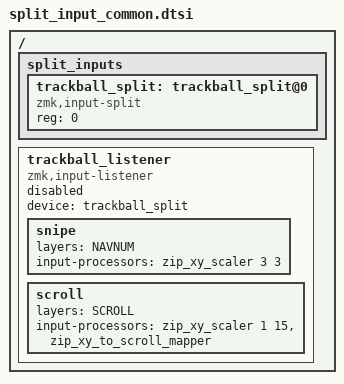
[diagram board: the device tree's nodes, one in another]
#include <dt-bindings/zmk/input_transform.h>
#include <input/processors.dtsi>

#define BASE 0
#define NAVNUM 1
#define SYMBOL 2
#define MEDIA 3
#define MOUSE 4
#define SCROLL 5 

/ {
  split_inputs {
    #address-cells = <1>;
    #size-cells = <0>;

    trackball_split: trackball_split@0 {
      compatible = "zmk,input-split";
      reg = <0>;
    };
  };

  trackball_listener: trackball_listener {
    compatible = "zmk,input-listener";
    status = "disabled";
    device = <&trackball_split>;

    snipe {
      layers = <NAVNUM>;
      input-processors = <&zip_xy_scaler 3 3>;
    };

    scroll {
      layers = <SCROLL>;
      input-processors = <&zip_xy_scaler 1 15>, <&zip_xy_to_scroll_mapper>;
    };
  };
};

